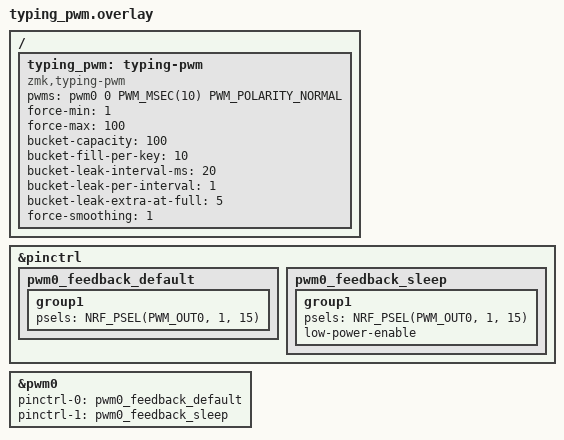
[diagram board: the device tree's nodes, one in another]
#include <zephyr/dt-bindings/pwm/pwm.h>

&pinctrl {
    pwm0_feedback_default: pwm0_feedback_default {
        group1 {
            psels = <NRF_PSEL(PWM_OUT0, 1, 15)>;
        };
    };

    pwm0_feedback_sleep: pwm0_feedback_sleep {
        group1 {
            psels = <NRF_PSEL(PWM_OUT0, 1, 15)>;
            low-power-enable;
        };
    };
};

/ {
    typing_pwm: typing-pwm {
        compatible = "zmk,typing-pwm";
        pwms = <&pwm0 0 PWM_MSEC(10) PWM_POLARITY_NORMAL>;
        force-min = <1>;
        force-max = <100>;
        bucket-capacity = <100>;
        bucket-fill-per-key = <10>;
        bucket-leak-interval-ms = <20>;
        bucket-leak-per-interval = <1>;
        bucket-leak-extra-at-full = <5>;
        force-smoothing = <1>;
    };
};

&pwm0 {
    status = "okay";
    pinctrl-0 = <&pwm0_feedback_default>;
    pinctrl-1 = <&pwm0_feedback_sleep>;
    pinctrl-names = "default", "sleep";
};
